VERSION "DeviceStatus v1"

NS_ :

BS_:

BU_: TEENSY1 TEENSY2 TEENSY3 TEENSY4 HOST

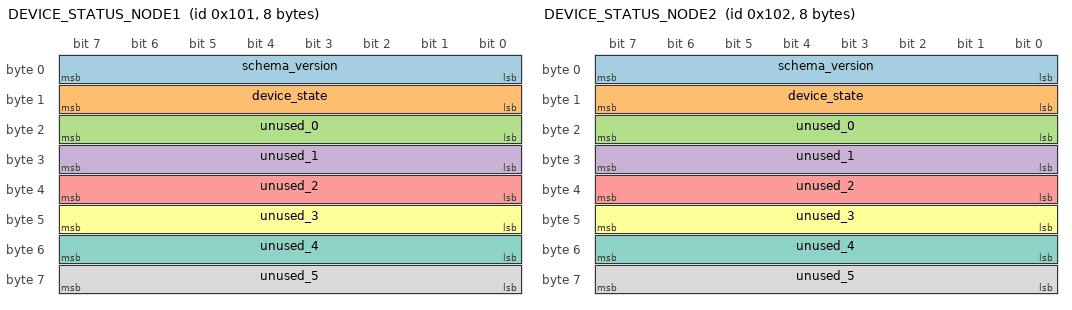
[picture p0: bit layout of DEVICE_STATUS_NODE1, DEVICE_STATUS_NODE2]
BO_ 257 DEVICE_STATUS_NODE1: 8 TEENSY1
 SG_ schema_version : 0|8@1+  (1,0) [0|255] "" HOST
 SG_ device_state   : 8|8@1+  (1,0) [0|2]   "" HOST
 SG_ unused_0       : 16|8@1+ (1,0) [0|255] "" HOST
 SG_ unused_1       : 24|8@1+ (1,0) [0|255] "" HOST
 SG_ unused_2       : 32|8@1+ (1,0) [0|255] "" HOST
 SG_ unused_3       : 40|8@1+ (1,0) [0|255] "" HOST
 SG_ unused_4       : 48|8@1+ (1,0) [0|255] "" HOST
 SG_ unused_5       : 56|8@1+ (1,0) [0|255] "" HOST

BO_ 258 DEVICE_STATUS_NODE2: 8 TEENSY2
 SG_ schema_version : 0|8@1+  (1,0) [0|255] "" HOST
 SG_ device_state   : 8|8@1+  (1,0) [0|2]   "" HOST
 SG_ unused_0       : 16|8@1+ (1,0) [0|255] "" HOST
 SG_ unused_1       : 24|8@1+ (1,0) [0|255] "" HOST
 SG_ unused_2       : 32|8@1+ (1,0) [0|255] "" HOST
 SG_ unused_3       : 40|8@1+ (1,0) [0|255] "" HOST
 SG_ unused_4       : 48|8@1+ (1,0) [0|255] "" HOST
 SG_ unused_5       : 56|8@1+ (1,0) [0|255] "" HOST

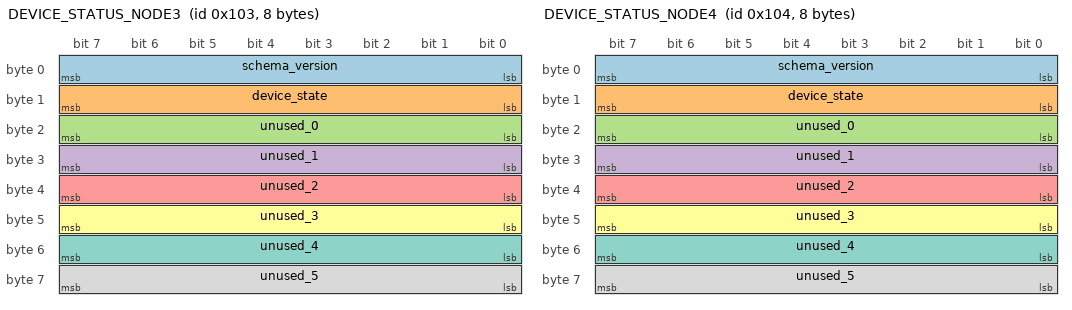
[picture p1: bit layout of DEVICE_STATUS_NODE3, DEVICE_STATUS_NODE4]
BO_ 259 DEVICE_STATUS_NODE3: 8 TEENSY3
 SG_ schema_version : 0|8@1+  (1,0) [0|255] "" HOST
 SG_ device_state   : 8|8@1+  (1,0) [0|2]   "" HOST
 SG_ unused_0       : 16|8@1+ (1,0) [0|255] "" HOST
 SG_ unused_1       : 24|8@1+ (1,0) [0|255] "" HOST
 SG_ unused_2       : 32|8@1+ (1,0) [0|255] "" HOST
 SG_ unused_3       : 40|8@1+ (1,0) [0|255] "" HOST
 SG_ unused_4       : 48|8@1+ (1,0) [0|255] "" HOST
 SG_ unused_5       : 56|8@1+ (1,0) [0|255] "" HOST

BO_ 260 DEVICE_STATUS_NODE4: 8 TEENSY4
 SG_ schema_version : 0|8@1+  (1,0) [0|255] "" HOST
 SG_ device_state   : 8|8@1+  (1,0) [0|2]   "" HOST
 SG_ unused_0       : 16|8@1+ (1,0) [0|255] "" HOST
 SG_ unused_1       : 24|8@1+ (1,0) [0|255] "" HOST
 SG_ unused_2       : 32|8@1+ (1,0) [0|255] "" HOST
 SG_ unused_3       : 40|8@1+ (1,0) [0|255] "" HOST
 SG_ unused_4       : 48|8@1+ (1,0) [0|255] "" HOST
 SG_ unused_5       : 56|8@1+ (1,0) [0|255] "" HOST

VAL_ 256 device_state 0 "NODE_INIT" 1 "NODE_ACTIVE" 2 "NODE_FAULT";

CM_ BO_ 256 "Device status message. Actual firmware sends this at CAN ID 0x100 + nodeData.id.";
CM_ SG_ 256 schema_version "Schema version byte from nodeData.schema_version.";
CM_ SG_ 256 device_state "Raw node state enum from nodeData.state.";

BA_DEF_ BO_ "GenMsgCycleTime" INT 0 65535;
BA_ "GenMsgCycleTime" BO_ 257 1000;
BA_ "GenMsgCycleTime" BO_ 258 1000;
BA_ "GenMsgCycleTime" BO_ 259 1000;
BA_ "GenMsgCycleTime" BO_ 260 1000;
